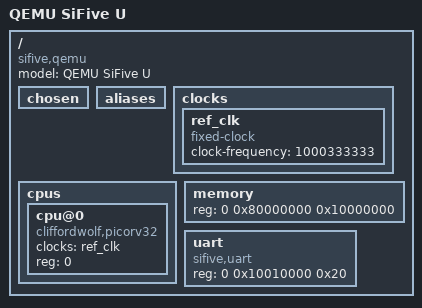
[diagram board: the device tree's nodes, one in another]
// SPDX-License-Identifier: GPL-2.0-only

/dts-v1/;

/ {
	model = "QEMU SiFive U";
	compatible = "sifive,qemu";

	#address-cells = <2>;
	#size-cells = <1>;

	chosen { };
	aliases { };

	clocks {
		ref_clk: ref_clk {
			#clock-cells = <0>;
			compatible = "fixed-clock";
			clock-frequency = <1000333333>;
		};
	};

	cpus {
		#address-cells = <1>;
		#size-cells = <0>;

		cpu@0 {
			device_type = "cpu";
			compatible = "cliffordwolf,picorv32";
			clocks = <&ref_clk>;
			reg = <0>;
		};
	};

	memory {
		device_type = "memory";
		reg = <0 0x80000000 0x10000000>;
	};

	uart: uart {
		compatible = "sifive,uart";
		reg = <0 0x10010000 0x20>;
		status = "okay";
	};
};
